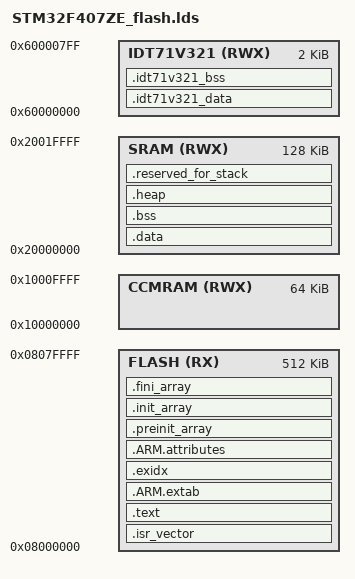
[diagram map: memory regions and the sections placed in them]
/* Generated by LinkerScriptGenerator [http://visualgdb.com/tools/LinkerScriptGenerator]
 * Target: STM32F407ZE
 * The file is provided under the BSD license.
 */

ENTRY(Reset_Handler)

MEMORY
{
	FLASH (RX)   : ORIGIN = 0x08000000, LENGTH = 512K
	SRAM (RWX)   : ORIGIN = 0x20000000, LENGTH = 128K
	CCMRAM (RWX) : ORIGIN = 0x10000000, LENGTH = 64K
	/* --- begin generated external memories -- */
	IDT71V321 (RWX) : ORIGIN = 0x60000000, LENGTH = 2048
	/* --- end generated external memories -- */
}

_estack = 0x20020000;

SECTIONS
{
	.isr_vector :
	{
		. = ALIGN(4);
		KEEP(*(.isr_vector))
		. = ALIGN(4);
	} > FLASH

	.text :
	{
		. = ALIGN(4);
		_stext = .;

		*(.text)
		*(.text*)
		*(.rodata)
		*(.rodata*)
		*(.glue_7)
		*(.glue_7t)
		KEEP(*(.init))
		KEEP(*(.fini))
		. = ALIGN(4);
		_etext = .;

	} > FLASH

	.ARM.extab :
	{
		. = ALIGN(4);
		*(.ARM.extab)
		*(.gnu.linkonce.armextab.*)
		. = ALIGN(4);
	} > FLASH

	.exidx :
	{
		. = ALIGN(4);
		PROVIDE(__exidx_start = .);
		*(.ARM.exidx*)
		. = ALIGN(4);
		PROVIDE(__exidx_end = .);
	} > FLASH

	.ARM.attributes :
	{
		*(.ARM.attributes)
	} > FLASH

	.preinit_array :
	{
		PROVIDE(__preinit_array_start = .);
		KEEP(*(.preinit_array*))
		PROVIDE(__preinit_array_end = .);
	} > FLASH

	.init_array :
	{
		PROVIDE(__init_array_start = .);
		KEEP(*(SORT(.init_array.*)))
		KEEP(*(.init_array*))
		PROVIDE(__init_array_end = .);
	} > FLASH

	.fini_array :
	{
		PROVIDE(__fini_array_start = .);
		KEEP(*(.fini_array*))
		KEEP(*(SORT(.fini_array.*)))
		PROVIDE(__fini_array_end = .);
	} > FLASH

	. = ALIGN(4);
	_sidata = .;

	.data : AT(_sidata)
	{
		. = ALIGN(4);
		_sdata = .;

		PROVIDE(__data_start__ = _sdata);
		*(.data)
		*(.data*)
		. = ALIGN(4);
		_edata = .;

		PROVIDE(__data_end__ = _edata);
	} > SRAM

	.bss :
	{
		. = ALIGN(4);
		_sbss = .;

		PROVIDE(__bss_start__ = _sbss);
		*(.bss)
		*(.bss*)
		*(COMMON)
		. = ALIGN(4);
		_ebss = .;

		PROVIDE(__bss_end__ = _ebss);
	} > SRAM
	/* --- begin generated external memory sections -- */
	. = _sidata + SIZEOF(.data);
	. = ALIGN(4);
	_siidt71v321_data = .;

	.idt71v321_data : AT(_siidt71v321_data)
	{
		. = ALIGN(4);
		_sidt71v321_data = .;

		PROVIDE(__idt71v321_data_start = _sidt71v321_data);
		*(.idt71v321_data)
		*(.idt71v321_data*)
		. = ALIGN(4);
		_eidt71v321_data = .;

		PROVIDE(__idt71v321_data_end = _eidt71v321_data);
	} > IDT71V321

	.idt71v321_bss (NOLOAD) :
	{
		. = ALIGN(4);
		_sidt71v321_bss = .;

		PROVIDE(__idt71v321_bss_start = _sidt71v321_bss);
		*(.idt71v321_bss)
		*(.idt71v321_bss*)
		. = ALIGN(4);
		_eidt71v321_bss = .;

		PROVIDE(__idt71v321_bss_end = _eidt71v321_bss);
	} > IDT71V321

	/* --- end generated external memory sections -- */


	PROVIDE(end = .);

	.heap (NOLOAD) :
	{
		. = ALIGN(4);
		PROVIDE(__heap_start__ = .);
		KEEP(*(.heap))
		. = ALIGN(4);
		PROVIDE(__heap_end__ = .);
	} > SRAM

	.reserved_for_stack (NOLOAD) :
	{
		. = ALIGN(4);
		PROVIDE(__reserved_for_stack_start__ = .);
		KEEP(*(.reserved_for_stack))
		. = ALIGN(4);
		PROVIDE(__reserved_for_stack_end__ = .);
	} > SRAM

}

